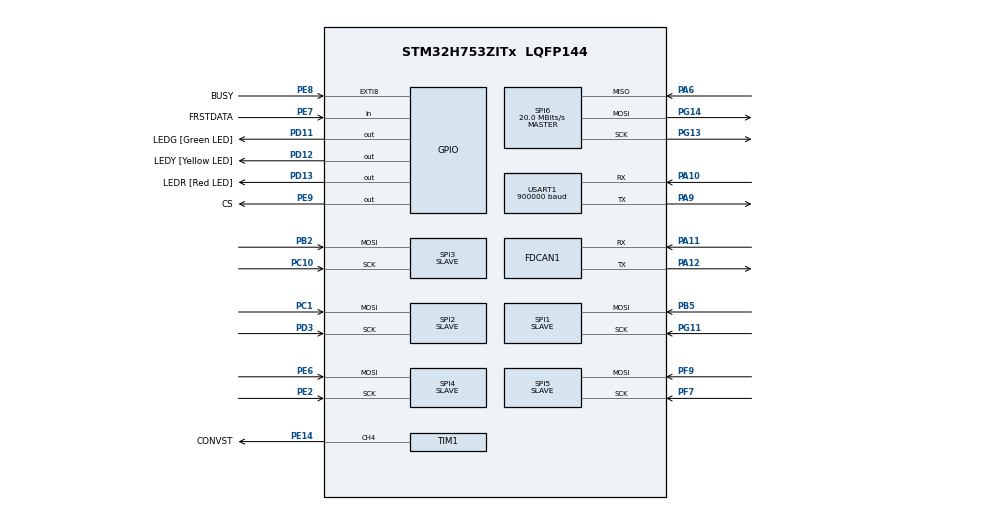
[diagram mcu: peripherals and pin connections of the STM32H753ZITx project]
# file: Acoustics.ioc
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ADC3.AWD1HighThreshold=16067
ADC3.AWD1ITMode=ENABLE
ADC3.AWD1LowThreshold=10900
ADC3.Channel-0\#ChannelRegularConversion=ADC_CHANNEL_TEMPSENSOR
ADC3.ClockPrescaler=ADC_CLOCK_ASYNC_DIV8
ADC3.ClockPrescalerADC3=ADC_CLOCK_ASYNC_DIV1
ADC3.ContinuousConvMode=DISABLE
ADC3.ConversionDataManagement=ADC_CONVERSIONDATA_DR
ADC3.EOCSelection=ADC_EOC_SINGLE_CONV
ADC3.EnableAnalogWatchDog1=true
ADC3.ExternalTrigConv=ADC_EXTERNALTRIG_T6_TRGO
ADC3.NbrOfConversion=1
ADC3.NbrOfConversionFlag=1
ADC3.OffsetNumber-0\#ChannelRegularConversion=ADC_OFFSET_NONE
ADC3.OffsetSignedSaturation-0\#ChannelRegularConversion=DISABLE
ADC3.Overrun=ADC_OVR_DATA_PRESERVED
ADC3.OversamplingMode=DISABLE
ADC3.Rank-0\#ChannelRegularConversion=1
ADC3.Ratio=1
ADC3.SamplingTime-0\#ChannelRegularConversion=ADC_SAMPLETIME_810CYCLES_5
ADC3.WatchdogChannel=ADC_CHANNEL_TEMPSENSOR
Bdma.ADC3.1.Direction=DMA_PERIPH_TO_MEMORY
Bdma.ADC3.1.EventEnable=DISABLE
Bdma.ADC3.1.Instance=BDMA_Channel1
Bdma.ADC3.1.MemDataAlignment=DMA_MDATAALIGN_HALFWORD
Bdma.ADC3.1.MemInc=DMA_MINC_DISABLE
Bdma.ADC3.1.Mode=DMA_CIRCULAR
Bdma.ADC3.1.PeriphDataAlignment=DMA_PDATAALIGN_HALFWORD
Bdma.ADC3.1.PeriphInc=DMA_PINC_DISABLE
Bdma.ADC3.1.Polarity=HAL_DMAMUX_REQ_GEN_RISING
Bdma.ADC3.1.Priority=DMA_PRIORITY_LOW
Bdma.ADC3.1.RequestNumber=1
Bdma.ADC3.1.SignalID=NONE
Bdma.ADC3.1.SyncEnable=DISABLE
Bdma.ADC3.1.SyncPolarity=HAL_DMAMUX_SYNC_NO_EVENT
Bdma.ADC3.1.SyncRequestNumber=1
Bdma.ADC3.1.SyncSignalID=NONE
Bdma.Request0=SPI6_RX
Bdma.Request1=ADC3
Bdma.RequestsNb=2
Bdma.SPI6_RX.0.Direction=DMA_PERIPH_TO_MEMORY
Bdma.SPI6_RX.0.EventEnable=DISABLE
Bdma.SPI6_RX.0.Instance=BDMA_Channel0
Bdma.SPI6_RX.0.MemDataAlignment=DMA_MDATAALIGN_HALFWORD
Bdma.SPI6_RX.0.MemInc=DMA_MINC_ENABLE
Bdma.SPI6_RX.0.Mode=DMA_CIRCULAR
Bdma.SPI6_RX.0.PeriphDataAlignment=DMA_PDATAALIGN_HALFWORD
Bdma.SPI6_RX.0.PeriphInc=DMA_PINC_DISABLE
Bdma.SPI6_RX.0.Polarity=HAL_DMAMUX_REQ_GEN_RISING
Bdma.SPI6_RX.0.Priority=DMA_PRIORITY_LOW
Bdma.SPI6_RX.0.RequestNumber=1
Bdma.SPI6_RX.0.SignalID=NONE
Bdma.SPI6_RX.0.SyncEnable=DISABLE
Bdma.SPI6_RX.0.SyncPolarity=HAL_DMAMUX_SYNC_NO_EVENT
Bdma.SPI6_RX.0.SyncRequestNumber=1
Bdma.SPI6_RX.0.SyncSignalID=NONE
CORTEX_M7.default_mode_Activation=1
Dma.Request0=SPI2_RX
Dma.Request1=SPI3_RX
Dma.Request2=SPI4_RX
Dma.Request3=SPI5_RX
Dma.Request4=SPI1_RX
Dma.Request5=TIM1_CH4
Dma.Request6=USART1_TX
Dma.SPI1_RX.4.Direction=DMA_PERIPH_TO_MEMORY
Dma.SPI1_RX.4.EventEnable=DISABLE
Dma.SPI1_RX.4.FIFOMode=DMA_FIFOMODE_DISABLE
Dma.SPI1_RX.4.Instance=DMA1_Stream0
Dma.SPI1_RX.4.MemDataAlignment=DMA_MDATAALIGN_HALFWORD
Dma.SPI1_RX.4.MemInc=DMA_MINC_ENABLE
Dma.SPI1_RX.4.Mode=DMA_CIRCULAR
Dma.SPI1_RX.4.PeriphDataAlignment=DMA_PDATAALIGN_HALFWORD
Dma.SPI1_RX.4.PeriphInc=DMA_PINC_DISABLE
Dma.SPI1_RX.4.Polarity=HAL_DMAMUX_REQ_GEN_RISING
Dma.SPI1_RX.4.Priority=DMA_PRIORITY_MEDIUM
Dma.SPI1_RX.4.RequestNumber=1
Dma.SPI1_RX.4.SignalID=NONE
Dma.SPI1_RX.4.SyncEnable=DISABLE
Dma.SPI1_RX.4.SyncPolarity=HAL_DMAMUX_SYNC_NO_EVENT
Dma.SPI1_RX.4.SyncRequestNumber=1
Dma.SPI1_RX.4.SyncSignalID=NONE
Dma.SPI2_RX.0.Direction=DMA_PERIPH_TO_MEMORY
Dma.SPI2_RX.0.EventEnable=DISABLE
Dma.SPI2_RX.0.FIFOMode=DMA_FIFOMODE_DISABLE
Dma.SPI2_RX.0.Instance=DMA1_Stream1
Dma.SPI2_RX.0.MemDataAlignment=DMA_MDATAALIGN_HALFWORD
Dma.SPI2_RX.0.MemInc=DMA_MINC_ENABLE
Dma.SPI2_RX.0.Mode=DMA_CIRCULAR
Dma.SPI2_RX.0.PeriphDataAlignment=DMA_PDATAALIGN_HALFWORD
Dma.SPI2_RX.0.PeriphInc=DMA_PINC_DISABLE
Dma.SPI2_RX.0.Polarity=HAL_DMAMUX_REQ_GEN_RISING
Dma.SPI2_RX.0.Priority=DMA_PRIORITY_VERY_HIGH
Dma.SPI2_RX.0.RequestNumber=1
Dma.SPI2_RX.0.SignalID=NONE
Dma.SPI2_RX.0.SyncEnable=DISABLE
Dma.SPI2_RX.0.SyncPolarity=HAL_DMAMUX_SYNC_NO_EVENT
Dma.SPI2_RX.0.SyncRequestNumber=1
Dma.SPI2_RX.0.SyncSignalID=NONE
Dma.SPI3_RX.1.Direction=DMA_PERIPH_TO_MEMORY
Dma.SPI3_RX.1.EventEnable=DISABLE
Dma.SPI3_RX.1.FIFOMode=DMA_FIFOMODE_DISABLE
Dma.SPI3_RX.1.Instance=DMA1_Stream2
Dma.SPI3_RX.1.MemDataAlignment=DMA_MDATAALIGN_HALFWORD
Dma.SPI3_RX.1.MemInc=DMA_MINC_ENABLE
Dma.SPI3_RX.1.Mode=DMA_CIRCULAR
Dma.SPI3_RX.1.PeriphDataAlignment=DMA_PDATAALIGN_HALFWORD
Dma.SPI3_RX.1.PeriphInc=DMA_PINC_DISABLE
Dma.SPI3_RX.1.Polarity=HAL_DMAMUX_REQ_GEN_RISING
Dma.SPI3_RX.1.Priority=DMA_PRIORITY_MEDIUM
Dma.SPI3_RX.1.RequestNumber=1
Dma.SPI3_RX.1.SignalID=NONE
Dma.SPI3_RX.1.SyncEnable=DISABLE
Dma.SPI3_RX.1.SyncPolarity=HAL_DMAMUX_SYNC_NO_EVENT
Dma.SPI3_RX.1.SyncRequestNumber=1
Dma.SPI3_RX.1.SyncSignalID=NONE
Dma.SPI4_RX.2.Direction=DMA_PERIPH_TO_MEMORY
Dma.SPI4_RX.2.EventEnable=DISABLE
Dma.SPI4_RX.2.FIFOMode=DMA_FIFOMODE_DISABLE
Dma.SPI4_RX.2.Instance=DMA1_Stream3
Dma.SPI4_RX.2.MemDataAlignment=DMA_MDATAALIGN_HALFWORD
Dma.SPI4_RX.2.MemInc=DMA_MINC_ENABLE
Dma.SPI4_RX.2.Mode=DMA_CIRCULAR
Dma.SPI4_RX.2.PeriphDataAlignment=DMA_PDATAALIGN_HALFWORD
Dma.SPI4_RX.2.PeriphInc=DMA_PINC_DISABLE
Dma.SPI4_RX.2.Polarity=HAL_DMAMUX_REQ_GEN_RISING
Dma.SPI4_RX.2.Priority=DMA_PRIORITY_MEDIUM
Dma.SPI4_RX.2.RequestNumber=1
Dma.SPI4_RX.2.SignalID=NONE
Dma.SPI4_RX.2.SyncEnable=DISABLE
Dma.SPI4_RX.2.SyncPolarity=HAL_DMAMUX_SYNC_NO_EVENT
Dma.SPI4_RX.2.SyncRequestNumber=1
Dma.SPI4_RX.2.SyncSignalID=NONE
Dma.SPI5_RX.3.Direction=DMA_PERIPH_TO_MEMORY
Dma.SPI5_RX.3.EventEnable=DISABLE
Dma.SPI5_RX.3.FIFOMode=DMA_FIFOMODE_DISABLE
Dma.SPI5_RX.3.Instance=DMA1_Stream4
Dma.SPI5_RX.3.MemDataAlignment=DMA_MDATAALIGN_HALFWORD
Dma.SPI5_RX.3.MemInc=DMA_MINC_ENABLE
Dma.SPI5_RX.3.Mode=DMA_CIRCULAR
Dma.SPI5_RX.3.PeriphDataAlignment=DMA_PDATAALIGN_HALFWORD
Dma.SPI5_RX.3.PeriphInc=DMA_PINC_DISABLE
Dma.SPI5_RX.3.Polarity=HAL_DMAMUX_REQ_GEN_RISING
Dma.SPI5_RX.3.Priority=DMA_PRIORITY_LOW
Dma.SPI5_RX.3.RequestNumber=1
Dma.SPI5_RX.3.SignalID=NONE
Dma.SPI5_RX.3.SyncEnable=DISABLE
Dma.SPI5_RX.3.SyncPolarity=HAL_DMAMUX_SYNC_NO_EVENT
Dma.SPI5_RX.3.SyncRequestNumber=1
Dma.SPI5_RX.3.SyncSignalID=NONE
Dma.TIM1_CH4.5.Direction=DMA_PERIPH_TO_MEMORY
Dma.TIM1_CH4.5.EventEnable=ENABLE
Dma.TIM1_CH4.5.FIFOMode=DMA_FIFOMODE_DISABLE
Dma.TIM1_CH4.5.Instance=DMA2_Stream0
Dma.TIM1_CH4.5.MemDataAlignment=DMA_MDATAALIGN_HALFWORD
Dma.TIM1_CH4.5.MemInc=DMA_MINC_ENABLE
Dma.TIM1_CH4.5.Mode=DMA_NORMAL
Dma.TIM1_CH4.5.PeriphDataAlignment=DMA_PDATAALIGN_HALFWORD
Dma.TIM1_CH4.5.PeriphInc=DMA_PINC_DISABLE
Dma.TIM1_CH4.5.Polarity=HAL_DMAMUX_REQ_GEN_RISING
Dma.TIM1_CH4.5.Priority=DMA_PRIORITY_LOW
Dma.TIM1_CH4.5.RequestNumber=1
Dma.TIM1_CH4.5.SignalID=NONE
Dma.TIM1_CH4.5.SyncEnable=DISABLE
Dma.TIM1_CH4.5.SyncPolarity=HAL_DMAMUX_SYNC_NO_EVENT
Dma.TIM1_CH4.5.SyncRequestNumber=1
Dma.TIM1_CH4.5.SyncSignalID=NONE
Dma.USART1_TX.6.Direction=DMA_MEMORY_TO_PERIPH
Dma.USART1_TX.6.EventEnable=DISABLE
Dma.USART1_TX.6.FIFOMode=DMA_FIFOMODE_DISABLE
Dma.USART1_TX.6.Instance=DMA1_Stream5
Dma.USART1_TX.6.MemDataAlignment=DMA_MDATAALIGN_BYTE
Dma.USART1_TX.6.MemInc=DMA_MINC_ENABLE
Dma.USART1_TX.6.Mode=DMA_NORMAL
Dma.USART1_TX.6.PeriphDataAlignment=DMA_PDATAALIGN_BYTE
Dma.USART1_TX.6.PeriphInc=DMA_PINC_DISABLE
Dma.USART1_TX.6.Polarity=HAL_DMAMUX_REQ_GEN_RISING
Dma.USART1_TX.6.Priority=DMA_PRIORITY_LOW
Dma.USART1_TX.6.RequestNumber=1
Dma.USART1_TX.6.SignalID=NONE
Dma.USART1_TX.6.SyncEnable=DISABLE
Dma.USART1_TX.6.SyncPolarity=HAL_DMAMUX_SYNC_NO_EVENT
Dma.USART1_TX.6.SyncRequestNumber=1
Dma.USART1_TX.6.SyncSignalID=NONE
FDCAN1.AutoRetransmission=DISABLE
FDCAN1.CalculateBaudRateNominal=500000
FDCAN1.CalculateTimeBitNominal=2000
FDCAN1.CalculateTimeQuantumNominal=12.5
FDCAN1.ClockCalibrationCCU=DISABLE
FDCAN1.DataSyncJumpWidth=10
FDCAN1.DataTimeSeg1=29
FDCAN1.DataTimeSeg2=10
FDCAN1.FrameFormat=FDCAN_FRAME_FD_BRS
FDCAN1.NominalPrescaler=1
FDCAN1.NominalSyncJumpWidth=40
FDCAN1.NominalTimeSeg1=119
FDCAN1.NominalTimeSeg2=40
FDCAN1.RxBufferSize=FDCAN_DATA_BYTES_16
FDCAN1.RxBuffersNbr=0
FDCAN1.RxFifo0ElmtSize=FDCAN_DATA_BYTES_16
FDCAN1.RxFifo0ElmtsNbr=8
FDCAN1.RxFifo1ElmtSize=FDCAN_DATA_BYTES_16
FDCAN1.RxFifo1ElmtsNbr=0
FDCAN1.StdFiltersNbr=1
FDCAN1.TxBuffersNbr=0
FDCAN1.TxElmtSize=FDCAN_DATA_BYTES_16
FDCAN1.TxFifoQueueElmtsNbr=16
Mcu.Family=STM32H7
Mcu.Name=STM32H753ZITx
Mcu.Package=LQFP144
Mdma.MDMA_Channel0.Request0=SW
Mdma.MDMA_Channel0.RequestsNb=1
Mdma.MDMA_Channel0.SW.0.BlockCount=1
Mdma.MDMA_Channel0.SW.0.BlockDataLength=256
Mdma.MDMA_Channel0.SW.0.BufferTransferLength=256
Mdma.MDMA_Channel0.SW.0.CircularMode=MDMA_LINEAR_LIST
Mdma.MDMA_Channel0.SW.0.DataAlignment=MDMA_DATAALIGN_PACKENABLE
Mdma.MDMA_Channel0.SW.0.DestBlockAddressOffset=0
Mdma.MDMA_Channel0.SW.0.DestBurst=MDMA_DEST_BURST_SINGLE
Mdma.MDMA_Channel0.SW.0.DestDataSize=MDMA_DEST_DATASIZE_WORD
Mdma.MDMA_Channel0.SW.0.DestinationInc=MDMA_DEST_INC_WORD
Mdma.MDMA_Channel0.SW.0.DstAddress=0
Mdma.MDMA_Channel0.SW.0.Endianness=MDMA_LITTLE_ENDIANNESS_PRESERVE
Mdma.MDMA_Channel0.SW.0.Instance=MDMA_Channel0
Mdma.MDMA_Channel0.SW.0.MaskAddress=0
Mdma.MDMA_Channel0.SW.0.MaskData=0
Mdma.MDMA_Channel0.SW.0.Priority=MDMA_PRIORITY_VERY_HIGH
Mdma.MDMA_Channel0.SW.0.Rank=First
Mdma.MDMA_Channel0.SW.0.SourceBlockAddressOffset=0
Mdma.MDMA_Channel0.SW.0.SourceBurst=MDMA_SOURCE_BURST_SINGLE
Mdma.MDMA_Channel0.SW.0.SourceDataSize=MDMA_SRC_DATASIZE_WORD
Mdma.MDMA_Channel0.SW.0.SourceInc=MDMA_SRC_INC_WORD
Mdma.MDMA_Channel0.SW.0.SrcAddress=0
Mdma.MDMA_Channel0.SW.0.TransferTriggerMode=MDMA_BLOCK_TRANSFER
Mdma.RequestSet0=MDMA_Channel0
Mdma.RequestSetsNb=1
NVIC.ADC3_IRQn=true\:0\:0\:false\:false\:true\:true\:true\:true
NVIC.BDMA_Channel0_IRQn=true\:0\:0\:false\:false\:true\:false\:true\:true
NVIC.BDMA_Channel1_IRQn=true\:0\:0\:false\:false\:true\:false\:true\:true
NVIC.DMA1_Stream0_IRQn=true\:14\:0\:true\:false\:true\:false\:true\:true
NVIC.DMA1_Stream1_IRQn=true\:14\:0\:true\:false\:true\:false\:true\:true
NVIC.DMA1_Stream2_IRQn=true\:14\:0\:true\:false\:true\:false\:true\:true
NVIC.DMA1_Stream3_IRQn=true\:14\:0\:true\:false\:true\:false\:true\:true
NVIC.DMA1_Stream4_IRQn=true\:14\:0\:true\:false\:true\:false\:true\:true
NVIC.DMA1_Stream5_IRQn=true\:0\:0\:false\:false\:true\:false\:true\:true
NVIC.DMA2_Stream0_IRQn=true\:0\:0\:false\:false\:true\:false\:true\:true
NVIC.DMAMUX1_OVR_IRQn=true\:0\:0\:false\:false\:true\:false\:true\:true
NVIC.EXTI9_5_IRQn=true\:2\:0\:true\:false\:true\:true\:true\:true
NVIC.FDCAN1_IT0_IRQn=true\:5\:0\:true\:false\:true\:true\:true\:true
NVIC.MDMA_IRQn=true\:0\:0\:false\:false\:true\:false\:true\:true
NVIC.PriorityGroup=NVIC_PRIORITYGROUP_4
NVIC.SPI1_IRQn=true\:13\:0\:true\:false\:true\:false\:true\:true
NVIC.SPI2_IRQn=true\:13\:0\:true\:false\:true\:false\:true\:true
NVIC.SPI3_IRQn=true\:13\:0\:true\:false\:true\:false\:true\:true
NVIC.SPI4_IRQn=true\:13\:0\:true\:false\:true\:false\:true\:true
NVIC.SPI5_IRQn=true\:13\:0\:true\:false\:true\:false\:true\:true
NVIC.SPI6_IRQn=true\:1\:0\:true\:false\:true\:true\:true\:true
PA10.GPIO_Speed=GPIO_SPEED_FREQ_VERY_HIGH
PA10.Mode=Asynchronous
PA10.Signal=USART1_RX
PA11.GPIO_Speed=GPIO_SPEED_FREQ_VERY_HIGH
PA11.Mode=FDCAN_Activate
PA11.Signal=FDCAN1_RX
PA12.GPIO_Speed=GPIO_SPEED_FREQ_VERY_HIGH
PA12.Mode=FDCAN_Activate
PA12.Signal=FDCAN1_TX
PA13\ (JTMS/SWDIO).Mode=Trace_Asynchronous_SW
PA13\ (JTMS/SWDIO).Signal=DEBUG_JTMS-SWDIO
PA14\ (JTCK/SWCLK).Mode=Trace_Asynchronous_SW
PA14\ (JTCK/SWCLK).Signal=DEBUG_JTCK-SWCLK
PA6.GPIO_Speed=GPIO_SPEED_FREQ_VERY_HIGH
PA6.Mode=Full_Duplex_Master
PA6.Signal=SPI6_MISO
PA9.GPIO_Speed=GPIO_SPEED_FREQ_VERY_HIGH
PA9.Mode=Asynchronous
PA9.Signal=USART1_TX
PB2.GPIO_Speed=GPIO_SPEED_FREQ_VERY_HIGH
PB2.Mode=RX_Only_Simplex_Unidirect_Slave
PB2.Signal=SPI3_MOSI
PB3\ (JTDO/TRACESWO).Mode=Trace_Asynchronous_SW
PB3\ (JTDO/TRACESWO).Signal=DEBUG_JTDO-SWO
PB5.GPIO_Mode=GPIO_MODE_AF_PP
PB5.GPIO_PuPd=GPIO_NOPULL
PB5.GPIO_Speed=GPIO_SPEED_FREQ_VERY_HIGH
PB5.Mode=RX_Only_Simplex_Unidirect_Slave
PB5.Signal=SPI1_MOSI
PC1.GPIO_Speed=GPIO_SPEED_FREQ_VERY_HIGH
PC1.Mode=RX_Only_Simplex_Unidirect_Slave
PC1.Signal=SPI2_MOSI
PC10.GPIO_Speed=GPIO_SPEED_FREQ_VERY_HIGH
PC10.Mode=RX_Only_Simplex_Unidirect_Slave
PC10.Signal=SPI3_SCK
PC14-OSC32_IN\ (OSC32_IN).Mode=LSE-External-Oscillator
PC14-OSC32_IN\ (OSC32_IN).Signal=RCC_OSC32_IN
PC15-OSC32_OUT\ (OSC32_OUT).Mode=LSE-External-Oscillator
PC15-OSC32_OUT\ (OSC32_OUT).Signal=RCC_OSC32_OUT
PD11.GPIO_Label=LEDG [Green LED]
PD11.Signal=GPIO_Output
PD12.GPIO_Label=LEDY [Yellow LED]
PD12.Signal=GPIO_Output
PD13.GPIO_Label=LEDR [Red LED]
PD13.Signal=GPIO_Output
PD3.GPIO_Speed=GPIO_SPEED_FREQ_VERY_HIGH
PD3.Mode=RX_Only_Simplex_Unidirect_Slave
PD3.Signal=SPI2_SCK
PE14.GPIO_Label=CONVST
PE14.GPIO_Speed=GPIO_SPEED_FREQ_VERY_HIGH
PE14.Signal=S_TIM1_CH4
PE2.GPIO_Speed=GPIO_SPEED_FREQ_VERY_HIGH
PE2.Mode=RX_Only_Simplex_Unidirect_Slave
PE2.Signal=SPI4_SCK
PE6.GPIO_Speed=GPIO_SPEED_FREQ_VERY_HIGH
PE6.Mode=RX_Only_Simplex_Unidirect_Slave
PE6.Signal=SPI4_MOSI
PE7.GPIO_Label=FRSTDATA
PE7.Signal=GPIO_Input
PE8.GPIO_Label=BUSY
PE8.Signal=GPXTI8
PE9.GPIO_Label=CS
PE9.PinState=GPIO_PIN_SET
PE9.Signal=GPIO_Output
PF7.GPIO_Speed=GPIO_SPEED_FREQ_VERY_HIGH
PF7.Mode=RX_Only_Simplex_Unidirect_Slave
PF7.Signal=SPI5_SCK
PF9.GPIO_Speed=GPIO_SPEED_FREQ_VERY_HIGH
PF9.Mode=RX_Only_Simplex_Unidirect_Slave
PF9.Signal=SPI5_MOSI
PG11.GPIO_Mode=GPIO_MODE_AF_PP
PG11.GPIO_PuPd=GPIO_NOPULL
PG11.GPIO_Speed=GPIO_SPEED_FREQ_VERY_HIGH
PG11.Mode=RX_Only_Simplex_Unidirect_Slave
PG11.Signal=SPI1_SCK
PG13.GPIO_Speed=GPIO_SPEED_FREQ_VERY_HIGH
PG13.Mode=Full_Duplex_Master
PG13.Signal=SPI6_SCK
PG14.GPIO_Speed=GPIO_SPEED_FREQ_VERY_HIGH
PG14.Mode=Full_Duplex_Master
PG14.Signal=SPI6_MOSI
PH0-OSC_IN\ (PH0).Mode=HSE-External-Clock-Source
PH0-OSC_IN\ (PH0).Signal=RCC_OSC_IN
ProjectManager.HeapSize=0x200
ProjectManager.StackSize=0x400
ProjectManager.TargetToolchain=STM32CubeIDE
RCC.ADCFreq_Value=80000000
RCC.APB1Freq_Value=120000000
RCC.APB2Freq_Value=120000000
RCC.APB3Freq_Value=120000000
RCC.APB4Freq_Value=120000000
RCC.CKPERSourceSelection=RCC_CLKPSOURCE_HSE
RCC.CortexFreq_Value=480000000
RCC.D1PPRE=RCC_APB3_DIV2
RCC.D2PPRE1=RCC_APB1_DIV2
RCC.D2PPRE2=RCC_APB2_DIV2
RCC.D3PPRE=RCC_APB4_DIV2
RCC.DIVM1=4
RCC.DIVM2=16
RCC.DIVN1=96
RCC.DIVN2=128
RCC.DIVN3=128
RCC.DIVP2=4
RCC.DIVQ1=5
RCC.DIVQ2=4
RCC.FDCANCLockSelection=RCC_FDCANCLKSOURCE_PLL2
RCC.FLatency-AdvancedSettings=FLASH_LATENCY_0
RCC.HCLKFreq_Value=240000000
RCC.HPRE=RCC_HCLK_DIV2
RCC.HSE_VALUE=40000000
RCC.PLL1_VCI_Range-AdvancedSettings=RCC_PLL1VCIRANGE_0
RCC.PLL1_VCO_SEL-AdvancedSettings=RCC_PLL1VCOMEDIUM
RCC.PLL2FRACN=0
RCC.PLL2_VCI_Range-AdvancedSettings=RCC_PLL2VCIRANGE_0
RCC.PLL2_VCO_SEL-AdvancedSettings=RCC_PLL2VCOMEDIUM
RCC.PLL3FRACN=0
RCC.PLL3_VCI_Range-AdvancedSettings=RCC_PLL3VCIRANGE_0
RCC.PLL3_VCO_SEL-AdvancedSettings=RCC_PLL3VCOWIDE
RCC.PLLFRACN=0
RCC.PLLSourceVirtual=RCC_PLLSOURCE_HSE
RCC.RTCClockSelection=RCC_RTCCLKSOURCE_LSE
RCC.SPI123CLockSelection=RCC_SPI123CLKSOURCE_PLL2
RCC.SPI6CLockSelection=RCC_SPI6CLKSOURCE_PLL2
RCC.SYSCLKFreq_VALUE=480000000
RCC.SYSCLKSource=RCC_SYSCLKSOURCE_PLLCLK
RCC.Spi45ClockSelection=RCC_SPI45CLKSOURCE_PLL2
RCC.USBFreq_Value=192000000
SH.S_TIM1_CH4.0=TIM1_CH4,PWM Generation4 CH4
SPI1.CLKPhase=SPI_PHASE_2EDGE
SPI1.CLKPolarity=SPI_POLARITY_HIGH
SPI1.DataSize=SPI_DATASIZE_16BIT
SPI1.Direction=SPI_DIRECTION_2LINES_RXONLY
SPI1.MasterKeepIOState=SPI_MASTER_KEEP_IO_STATE_DISABLE
SPI1.Mode=SPI_MODE_SLAVE
SPI1.VirtualType=VM_SLAVE
SPI2.CLKPhase=SPI_PHASE_2EDGE
SPI2.CLKPolarity=SPI_POLARITY_HIGH
SPI2.DataSize=SPI_DATASIZE_16BIT
SPI2.Direction=SPI_DIRECTION_2LINES_RXONLY
SPI2.Mode=SPI_MODE_SLAVE
SPI2.VirtualType=VM_SLAVE
SPI3.CLKPhase=SPI_PHASE_2EDGE
SPI3.CLKPolarity=SPI_POLARITY_HIGH
SPI3.DataSize=SPI_DATASIZE_16BIT
SPI3.Direction=SPI_DIRECTION_2LINES_RXONLY
SPI3.Mode=SPI_MODE_SLAVE
SPI3.VirtualType=VM_SLAVE
SPI4.CLKPhase=SPI_PHASE_2EDGE
SPI4.CLKPolarity=SPI_POLARITY_HIGH
SPI4.DataSize=SPI_DATASIZE_16BIT
SPI4.Direction=SPI_DIRECTION_2LINES_RXONLY
SPI4.Mode=SPI_MODE_SLAVE
SPI4.VirtualType=VM_SLAVE
SPI5.CLKPhase=SPI_PHASE_2EDGE
SPI5.CLKPolarity=SPI_POLARITY_HIGH
SPI5.DataSize=SPI_DATASIZE_16BIT
SPI5.Direction=SPI_DIRECTION_2LINES_RXONLY
SPI5.Mode=SPI_MODE_SLAVE
SPI5.VirtualType=VM_SLAVE
SPI6.BaudRatePrescaler=SPI_BAUDRATEPRESCALER_4
SPI6.CLKPhase=SPI_PHASE_1EDGE
SPI6.CLKPolarity=SPI_POLARITY_HIGH
SPI6.CalculateBaudRate=20.0 MBits/s
SPI6.DataSize=SPI_DATASIZE_16BIT
SPI6.Direction=SPI_DIRECTION_2LINES
SPI6.MasterKeepIOState=SPI_MASTER_KEEP_IO_STATE_ENABLE
SPI6.Mode=SPI_MODE_MASTER
SPI6.VirtualType=VM_MASTER
TIM1.Channel-PWM\ Generation4\ CH4=TIM_CHANNEL_4
TIM1.OC4Preload_PWM=ENABLE
TIM1.Period=1919
TIM1.Prescaler=0
TIM1.Pulse-PWM\ Generation4\ CH4=10
TIM6.Period=249
TIM6.Prescaler=3749
TIM6.TIM_MasterOutputTrigger=TIM_TRGO_UPDATE
USART1.BaudRate=900000
USART1.OverSampling=UART_OVERSAMPLING_16
USART1.VirtualMode-Asynchronous=VM_ASYNC
VP_ADC3_TempSens_Input.Mode=IN-TempSens
VP_CRC_VS_CRC.Mode=CRC_Activate
VP_MEMORYMAP_VS_MEMORYMAP.Mode=CurAppReg
VP_RTC_VS_RTC_Activate.Mode=RTC_Enabled
VP_TIM1_VS_ClockSourceINT.Mode=Internal
VP_TIM6_VS_ClockSourceINT.Mode=Enable_Timer
board=custom

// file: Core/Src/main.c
/* USER CODE BEGIN Header */
/**
 ******************************************************************************
 * @file           : main.c
 * @brief          : Main program body
 ******************************************************************************
 * @attention
 *
 * Copyright (c) 2026 STMicroelectronics.
 * All rights reserved.
 *
 * This software is licensed under terms that can be found in the LICENSE file
 * in the root directory of this software component.
 * If no LICENSE file comes with this software, it is provided AS-IS.
 *
 ******************************************************************************
 */
/* USER CODE END Header */
#include "main.h"

/* USER CODE BEGIN Includes */
#include "ad7606_driver.h"

#include "acoustics.h"
#include "can_interface.h"
#include "debug.h"
#include "interrupts.h"
#include <hydrophone_interface.h>

#include "utils.h"
#include "memory_placement.h"
#include "embedded_macros.h"

#include "find_peaks.h"
#include "dsp.h"
#include "cwt.h"
#include "hilbert.h"

#include "fast_mdma.h"
#include "stm_temp_driver.h"
#include "tdoa.h"

#include "stm32h753xx.h"
#include "stm32h7xx_hal.h"
#include "stm32h7xx_hal_gpio.h"
#include "stm32h7xx_hal_gpio_ex.h"
#include "stm32h7xx_hal_spi.h"
#include "stm32h7xx_hal_mdma.h"
#include "stm32h7xx_hal_fdcan.h"

#include "arm_math_types.h"
#include "arm_math.h"
#include "arm_const_structs.h"

#include <stdio.h>
#include <stdbool.h>
#include <stdint.h>
#include <stdlib.h>

/* USER CODE END Includes */

ADC_HandleTypeDef hadc3;
DMA_HandleTypeDef hdma_adc3;

CRC_HandleTypeDef hcrc;

FDCAN_HandleTypeDef hfdcan1;

RTC_HandleTypeDef hrtc;

SPI_HandleTypeDef hspi1;
SPI_HandleTypeDef hspi2;
SPI_HandleTypeDef hspi3;
SPI_HandleTypeDef hspi4;
SPI_HandleTypeDef hspi5;
SPI_HandleTypeDef hspi6;
DMA_HandleTypeDef hdma_spi1_rx;
DMA_HandleTypeDef hdma_spi2_rx;
DMA_HandleTypeDef hdma_spi3_rx;
DMA_HandleTypeDef hdma_spi4_rx;
DMA_HandleTypeDef hdma_spi5_rx;
DMA_HandleTypeDef hdma_spi6_rx;

TIM_HandleTypeDef htim1;
TIM_HandleTypeDef htim6;
DMA_HandleTypeDef hdma_tim1_ch4;

UART_HandleTypeDef huart1;
DMA_HandleTypeDef hdma_usart1_tx;

MDMA_HandleTypeDef hmdma_mdma_channel0_sw_0;
/* USER CODE BEGIN PV */

PLACE_IN_DTCM volatile statemachine_state program_state;
PLACE_IN_DTCM volatile statemachine_state prev_program_state;
PLACE_IN_DTCM uint8_t stale_data_patience;
PLACE_IN_DTCM uint8_t previous_target_block;

PLACE_IN_D3_SRAM float32_t stm32_temp;

/* USER CODE END PV */

void SystemClock_Config(void);
void PeriphCommonClock_Config(void);
static void MPU_Config(void);
static void MX_GPIO_Init(void);
static void MX_DMA_Init(void);
static void MX_MDMA_Init(void);
static void MX_BDMA_Init(void);
static void MX_FDCAN1_Init(void);
static void MX_SPI1_Init(void);
static void MX_SPI2_Init(void);
static void MX_SPI3_Init(void);
static void MX_SPI4_Init(void);
static void MX_SPI5_Init(void);
static void MX_SPI6_Init(void);
static void MX_USART1_UART_Init(void);
static void MX_CRC_Init(void);
static void MX_TIM1_Init(void);
static void MX_RTC_Init(void);
static void MX_ADC3_Init(void);
static void MX_TIM6_Init(void);

/* USER CODE BEGIN 0 */

void SWO_Init(void)
{
    /* Enable ITM and DWT */
    CoreDebug->DEMCR |= CoreDebug_DEMCR_TRCENA_Msk;

    /* ITM unlock */
    ITM->LAR = 0xC5ACCE55;

    /* Enable ITM port 0 */
    ITM->TCR |= ITM_TCR_ITMENA_Msk;
    ITM->TER |= (1UL << 0);  // Enable stimulus port 0
}

bool stale_data(uint8_t target_block){
	if(target_block == previous_target_block){

		if(unlikely(stale_data_patience-- == 0)){
			return true;
		}
	}else{
		stale_data_patience = STALE_DATA_PATIENCE;
	}
	previous_target_block = target_block;
	return false;
}
/* USER CODE END 0 */

int main(void)
{

  /* USER CODE BEGIN 1 */
	/*
	 * If hydrophone stream stops unexpectedly then:
	 * MAKE SURE HAL_SPI_IRQHandler IS NOT CALLED!!!!
	 * It WILL be there after every code generation
	 */
  /* USER CODE END 1 */

  /* MPU Configuration--------------------------------------------------------*/
  MPU_Config();

  /* MCU Configuration--------------------------------------------------------*/

  /* Reset of all peripherals, Initializes the Flash interface and the Systick. */
  HAL_Init();

  /* USER CODE BEGIN Init */
  SWO_Init();

  /* USER CODE END Init */

  /* Configure the system clock */
  SystemClock_Config();

  /* Configure the peripherals common clocks */
  PeriphCommonClock_Config();

  /* USER CODE BEGIN SysInit */
  utils_DWT_init();

  /* USER CODE END SysInit */

  /* Initialize all configured peripherals */
  MX_GPIO_Init();
  MX_DMA_Init();
  MX_MDMA_Init();
  MX_BDMA_Init();
  MX_FDCAN1_Init();
  MX_SPI1_Init();
  MX_SPI2_Init();
  MX_SPI3_Init();
  MX_SPI4_Init();
  MX_SPI5_Init();
  MX_SPI6_Init();
  MX_USART1_UART_Init();
  MX_CRC_Init();
  MX_TIM1_Init();
  MX_RTC_Init();
  MX_ADC3_Init();
  MX_TIM6_Init();
  /* USER CODE BEGIN 2 */
  //MDMA_UserInit();
	HAL_GPIO_WritePin(GREEN_LED, GPIO_PIN_SET);
	uint8_t msg[] = "USART1 OK\r\n";
	HAL_UART_Transmit(&huart1, msg, sizeof(msg) - 1, 100);
	can_init();
	stm_temp_sensor_init(&hadc3, &htim6);

//	float32_t hydrophone_positions_temp[N_HYDROPHONES][3] = { //this is in cm and must be converted
//			{0.0,0.0,0.0},
//			{0.0,0.0,0.0},
//			{32.3,-4.3,3.66},
//			{-6.6,34.7,1.66},
//			{-4.6,0.0,-34.34}
//	}; // these are the positions on the acoustics stand

	/*
	 * These are the hydrophone positions measured in meters
	 * Axis:
	 * 	positive x direction is forwards on the drone
	 * 	positive y direction is to the right on the drone
	 * 	positive z direction is downwards on the drone
	 *
	 * Each index corresponds to a filter:
	 * 	index 0 -> filter 1
	 * 	index 1 -> filter 2
	 * 	...
	 *
	 * The direction measured by acoustics is the direction from the origin of the hydrophones coordinate system
	 */
	float32_t hydrophone_positions_actual[N_HYDROPHONES][3] = {
			{ 0.130, 0.235,-0.215},
			{-0.130,-0.235, 0.215},
			{-0.130, 0.235,-0.215},
			{ 0.130,-0.235,-0.215},
			{ 0.130, 0.235, 0.215},
	};

	stale_data_patience = STALE_DATA_PATIENCE;
	previous_target_block = 0xFF;

	acoustics_init();
	hydrophone_interface_init(hydrophone_positions_actual);

	hydrophone_interface_start_datastream();
	program_state = STATE_SEARCHING;

  /* USER CODE END 2 */

  /* Infinite loop */
  /* USER CODE BEGIN WHILE */
	HAL_GPIO_WritePin(YELLOW_LED, GPIO_PIN_SET);

	uint8_t target_block = 0;
	uint8_t detection_patience = DETECTION_PATIENCE;

    while (1) {
    	switch(program_state){
    	case(STATE_SEARCHING): //STATE_SEARCHING
    		while(program_state == STATE_SEARCHING){
    			target_block = hydrophone_buffers_get_detection_block_pos_fast();
				uint8_t processing_half = !mdma_half;
				fast_MDMA_copy_block(hydrophone_buffers[0][target_block], detection_buffer[mdma_half], &hmdma_mdma_channel0_sw_0);

				hydrophone_interface_update_temp();

				if(unlikely(stale_data(target_block))){
					Error_Handler();
				}

				if(unlikely(acoustics_signal_present(processing_half))){
					program_state = STATE_PROCESSING;
					detection_patience = DETECTION_PATIENCE;
				}

				hydrophone_interface_wait_for_mdma();
    		}
		break;
    	case(STATE_PROCESSING):
			hydrophone_interface_stop_datastream();
			HAL_GPIO_WritePin(GREEN_LED, GPIO_PIN_RESET);

			can_ping();

			acoustics_prepare_data(target_block);
			acoustics_process_data();
			acoustics_clean_data();

			if(program_state == STATE_CAN_COMMUNICATE){
				prev_program_state = STATE_SIGNAL_PRESENT;
			}else{
				program_state = STATE_SIGNAL_PRESENT;
			}
			hydrophone_interface_restart_spi_and_buffers();
			hydrophone_interface_start_datastream();
			HAL_GPIO_WritePin(GREEN_LED, GPIO_PIN_SET);
		break;

    	case(STATE_SIGNAL_PRESENT): //For when the signal is still going even after we finished processing its arrival
    		while((program_state == STATE_SIGNAL_PRESENT) && detection_patience){
    			target_block = hydrophone_buffers_get_detection_block_pos_fast();
    			uint8_t processing_half = !mdma_half;
    			fast_MDMA_copy_block(hydrophone_buffers[0][target_block], detection_buffer[mdma_half], &hmdma_mdma_channel0_sw_0);

    			hydrophone_interface_update_temp();

				if(unlikely(stale_data(target_block))){
					HAL_GPIO_WritePin(RED_LED, GPIO_PIN_SET);
					utils_DWT_delay_ms(1000);
					Error_Handler();
				}

    			detection_patience--;
    			if(unlikely(acoustics_signal_present(processing_half))){
    				detection_patience = DETECTION_PATIENCE;
    			}

    			if(detection_patience == 0){
    				if(program_state == STATE_CAN_COMMUNICATE){
    					prev_program_state = STATE_SEARCHING;
    				}else{
    					program_state = STATE_SEARCHING;
    				}
    			}

    			hydrophone_interface_wait_for_mdma();
    		}
		break;
    	case(STATE_CAN_COMMUNICATE): //For when a can request is on the line
			can_handle_requests();
    		if(prev_program_state != STATE_CAN_COMMUNICATE){
    			program_state = prev_program_state;
    		}else{
    			program_state = STATE_ERROR;
    		}

		break;
    	case(STATE_STOPPED): // For when we received a stop request
    		can_stopped();
    		utils_DWT_delay_ms(500);
		break;
    	case(STATE_ERROR):
    			Error_Handler();
    	break;
    	default:
    		program_state = STATE_ERROR;
    	break;
    	}
    /* USER CODE END WHILE */

    /* USER CODE BEGIN 3 */
    }
    Error_Handler();
  /* USER CODE END 3 */
}

void SystemClock_Config(void)
{
  RCC_OscInitTypeDef RCC_OscInitStruct = {0};
  RCC_ClkInitTypeDef RCC_ClkInitStruct = {0};

  /** Supply configuration update enable
  */
  HAL_PWREx_ConfigSupply(PWR_LDO_SUPPLY);

  /** Configure the main internal regulator output voltage
  */
  __HAL_PWR_VOLTAGESCALING_CONFIG(PWR_REGULATOR_VOLTAGE_SCALE0);

  while(!__HAL_PWR_GET_FLAG(PWR_FLAG_VOSRDY)) {}

  /** Configure LSE Drive Capability
  */
  HAL_PWR_EnableBkUpAccess();
  __HAL_RCC_LSEDRIVE_CONFIG(RCC_LSEDRIVE_LOW);

  /** Initializes the RCC Oscillators according to the specified parameters
  * in the RCC_OscInitTypeDef structure.
  */
  RCC_OscInitStruct.OscillatorType = RCC_OSCILLATORTYPE_HSE|RCC_OSCILLATORTYPE_LSE;
  RCC_OscInitStruct.HSEState = RCC_HSE_BYPASS;
  RCC_OscInitStruct.LSEState = RCC_LSE_ON;
  RCC_OscInitStruct.PLL.PLLState = RCC_PLL_ON;
  RCC_OscInitStruct.PLL.PLLSource = RCC_PLLSOURCE_HSE;
  RCC_OscInitStruct.PLL.PLLM = 4;
  RCC_OscInitStruct.PLL.PLLN = 96;
  RCC_OscInitStruct.PLL.PLLP = 2;
  RCC_OscInitStruct.PLL.PLLQ = 5;
  RCC_OscInitStruct.PLL.PLLR = 2;
  RCC_OscInitStruct.PLL.PLLRGE = RCC_PLL1VCIRANGE_3;
  RCC_OscInitStruct.PLL.PLLVCOSEL = RCC_PLL1VCOWIDE;
  RCC_OscInitStruct.PLL.PLLFRACN = 0;
  if (HAL_RCC_OscConfig(&RCC_OscInitStruct) != HAL_OK)
  {
    Error_Handler();
  }

  /** Initializes the CPU, AHB and APB buses clocks
  */
  RCC_ClkInitStruct.ClockType = RCC_CLOCKTYPE_HCLK|RCC_CLOCKTYPE_SYSCLK
                              |RCC_CLOCKTYPE_PCLK1|RCC_CLOCKTYPE_PCLK2
                              |RCC_CLOCKTYPE_D3PCLK1|RCC_CLOCKTYPE_D1PCLK1;
  RCC_ClkInitStruct.SYSCLKSource = RCC_SYSCLKSOURCE_PLLCLK;
  RCC_ClkInitStruct.SYSCLKDivider = RCC_SYSCLK_DIV1;
  RCC_ClkInitStruct.AHBCLKDivider = RCC_HCLK_DIV2;
  RCC_ClkInitStruct.APB3CLKDivider = RCC_APB3_DIV2;
  RCC_ClkInitStruct.APB1CLKDivider = RCC_APB1_DIV2;
  RCC_ClkInitStruct.APB2CLKDivider = RCC_APB2_DIV2;
  RCC_ClkInitStruct.APB4CLKDivider = RCC_APB4_DIV2;

  if (HAL_RCC_ClockConfig(&RCC_ClkInitStruct, FLASH_LATENCY_4) != HAL_OK)
  {
    Error_Handler();
  }
}

void PeriphCommonClock_Config(void)
{
  RCC_PeriphCLKInitTypeDef PeriphClkInitStruct = {0};

  /** Initializes the peripherals clock
  */
  PeriphClkInitStruct.PeriphClockSelection = RCC_PERIPHCLK_SPI6|RCC_PERIPHCLK_ADC
                              |RCC_PERIPHCLK_SPI3|RCC_PERIPHCLK_SPI2
                              |RCC_PERIPHCLK_SPI1|RCC_PERIPHCLK_SPI4
                              |RCC_PERIPHCLK_SPI5|RCC_PERIPHCLK_FDCAN;
  PeriphClkInitStruct.PLL2.PLL2M = 16;
  PeriphClkInitStruct.PLL2.PLL2N = 128;
  PeriphClkInitStruct.PLL2.PLL2P = 4;
  PeriphClkInitStruct.PLL2.PLL2Q = 4;
  PeriphClkInitStruct.PLL2.PLL2R = 2;
  PeriphClkInitStruct.PLL2.PLL2RGE = RCC_PLL2VCIRANGE_1;
  PeriphClkInitStruct.PLL2.PLL2VCOSEL = RCC_PLL2VCOMEDIUM;
  PeriphClkInitStruct.PLL2.PLL2FRACN = 0;
  PeriphClkInitStruct.Spi123ClockSelection = RCC_SPI123CLKSOURCE_PLL2;
  PeriphClkInitStruct.Spi45ClockSelection = RCC_SPI45CLKSOURCE_PLL2;
  PeriphClkInitStruct.FdcanClockSelection = RCC_FDCANCLKSOURCE_PLL2;
  PeriphClkInitStruct.AdcClockSelection = RCC_ADCCLKSOURCE_PLL2;
  PeriphClkInitStruct.Spi6ClockSelection = RCC_SPI6CLKSOURCE_PLL2;
  if (HAL_RCCEx_PeriphCLKConfig(&PeriphClkInitStruct) != HAL_OK)
  {
    Error_Handler();
  }
}

static void MX_ADC3_Init(void)
{

  ADC_AnalogWDGConfTypeDef AnalogWDGConfig = {0};
  ADC_ChannelConfTypeDef sConfig = {0};

  /** Common config
  */
  hadc3.Instance = ADC3;
  hadc3.Init.ClockPrescaler = ADC_CLOCK_ASYNC_DIV8;
  hadc3.Init.Resolution = ADC_RESOLUTION_16B;
  hadc3.Init.ScanConvMode = ADC_SCAN_DISABLE;
  hadc3.Init.EOCSelection = ADC_EOC_SINGLE_CONV;
  hadc3.Init.LowPowerAutoWait = DISABLE;
  hadc3.Init.ContinuousConvMode = DISABLE;
  hadc3.Init.NbrOfConversion = 1;
  hadc3.Init.DiscontinuousConvMode = DISABLE;
  hadc3.Init.ExternalTrigConv = ADC_EXTERNALTRIG_T6_TRGO;
  hadc3.Init.ExternalTrigConvEdge = ADC_EXTERNALTRIGCONVEDGE_RISING;
  hadc3.Init.ConversionDataManagement = ADC_CONVERSIONDATA_DR;
  hadc3.Init.Overrun = ADC_OVR_DATA_PRESERVED;
  hadc3.Init.LeftBitShift = ADC_LEFTBITSHIFT_NONE;
  hadc3.Init.OversamplingMode = DISABLE;
  hadc3.Init.Oversampling.Ratio = 1;
  if (HAL_ADC_Init(&hadc3) != HAL_OK)
  {
    Error_Handler();
  }

  /** Configure Analog WatchDog 1
  */
  AnalogWDGConfig.WatchdogNumber = ADC_ANALOGWATCHDOG_1;
  AnalogWDGConfig.WatchdogMode = ADC_ANALOGWATCHDOG_SINGLE_REG;
  AnalogWDGConfig.Channel = ADC_CHANNEL_TEMPSENSOR;
  AnalogWDGConfig.ITMode = ENABLE;
  AnalogWDGConfig.HighThreshold = 16067;
  AnalogWDGConfig.LowThreshold = 10900;
  if (HAL_ADC_AnalogWDGConfig(&hadc3, &AnalogWDGConfig) != HAL_OK)
  {
    Error_Handler();
  }

  /** Configure Regular Channel
  */
  sConfig.Channel = ADC_CHANNEL_TEMPSENSOR;
  sConfig.Rank = ADC_REGULAR_RANK_1;
  sConfig.SamplingTime = ADC_SAMPLETIME_810CYCLES_5;
  sConfig.SingleDiff = ADC_SINGLE_ENDED;
  sConfig.OffsetNumber = ADC_OFFSET_NONE;
  sConfig.Offset = 0;
  sConfig.OffsetSignedSaturation = DISABLE;
  if (HAL_ADC_ConfigChannel(&hadc3, &sConfig) != HAL_OK)
  {
    Error_Handler();
  }

}

static void MX_CRC_Init(void)
{

  hcrc.Instance = CRC;
  hcrc.Init.DefaultPolynomialUse = DEFAULT_POLYNOMIAL_ENABLE;
  hcrc.Init.DefaultInitValueUse = DEFAULT_INIT_VALUE_ENABLE;
  hcrc.Init.InputDataInversionMode = CRC_INPUTDATA_INVERSION_NONE;
  hcrc.Init.OutputDataInversionMode = CRC_OUTPUTDATA_INVERSION_DISABLE;
  hcrc.InputDataFormat = CRC_INPUTDATA_FORMAT_BYTES;
  if (HAL_CRC_Init(&hcrc) != HAL_OK)
  {
    Error_Handler();
  }

}

static void MX_FDCAN1_Init(void)
{

  hfdcan1.Instance = FDCAN1;
  hfdcan1.Init.FrameFormat = FDCAN_FRAME_FD_BRS;
  hfdcan1.Init.Mode = FDCAN_MODE_NORMAL;
  hfdcan1.Init.AutoRetransmission = DISABLE;
  hfdcan1.Init.TransmitPause = DISABLE;
  hfdcan1.Init.ProtocolException = DISABLE;
  hfdcan1.Init.NominalPrescaler = 1;
  hfdcan1.Init.NominalSyncJumpWidth = 40;
  hfdcan1.Init.NominalTimeSeg1 = 119;
  hfdcan1.Init.NominalTimeSeg2 = 40;
  hfdcan1.Init.DataPrescaler = 1;
  hfdcan1.Init.DataSyncJumpWidth = 10;
  hfdcan1.Init.DataTimeSeg1 = 29;
  hfdcan1.Init.DataTimeSeg2 = 10;
  hfdcan1.Init.MessageRAMOffset = 0;
  hfdcan1.Init.StdFiltersNbr = 1;
  hfdcan1.Init.ExtFiltersNbr = 0;
  hfdcan1.Init.RxFifo0ElmtsNbr = 8;
  hfdcan1.Init.RxFifo0ElmtSize = FDCAN_DATA_BYTES_16;
  hfdcan1.Init.RxFifo1ElmtsNbr = 0;
  hfdcan1.Init.RxFifo1ElmtSize = FDCAN_DATA_BYTES_16;
  hfdcan1.Init.RxBuffersNbr = 0;
  hfdcan1.Init.RxBufferSize = FDCAN_DATA_BYTES_16;
  hfdcan1.Init.TxEventsNbr = 0;
  hfdcan1.Init.TxBuffersNbr = 0;
  hfdcan1.Init.TxFifoQueueElmtsNbr = 16;
  hfdcan1.Init.TxFifoQueueMode = FDCAN_TX_FIFO_OPERATION;
  hfdcan1.Init.TxElmtSize = FDCAN_DATA_BYTES_16;
  if (HAL_FDCAN_Init(&hfdcan1) != HAL_OK)
  {
    Error_Handler();
  }
  /* USER CODE BEGIN FDCAN1_Init 2 */
  FDCAN_FilterTypeDef filterConfig;
  filterConfig.IdType       = FDCAN_STANDARD_ID;
  filterConfig.FilterIndex  = 0;
  filterConfig.FilterType   = FDCAN_FILTER_MASK;
  filterConfig.FilterConfig = FDCAN_FILTER_TO_RXFIFO0;
  filterConfig.FilterID1    = 0x000;   // ID
  filterConfig.FilterID2    = 0x000;   // Mask: 0x000 = accept all

  HAL_FDCAN_ConfigFilter(&hfdcan1, &filterConfig);

  // Reject non-matching and remote frames (recommended)
  HAL_FDCAN_ConfigGlobalFilter(
      &hfdcan1,
      FDCAN_REJECT,         // Non-matching standard
      FDCAN_REJECT,         // Non-matching extended
      FDCAN_FILTER_REMOTE,  // Remote standard
      FDCAN_FILTER_REMOTE   // Remote extended
  );
  /* USER CODE END FDCAN1_Init 2 */

}

static void MX_RTC_Init(void)
{

  /** Initialize RTC Only
  */
  hrtc.Instance = RTC;
  hrtc.Init.HourFormat = RTC_HOURFORMAT_24;
  hrtc.Init.AsynchPrediv = 127;
  hrtc.Init.SynchPrediv = 255;
  hrtc.Init.OutPut = RTC_OUTPUT_DISABLE;
  hrtc.Init.OutPutPolarity = RTC_OUTPUT_POLARITY_HIGH;
  hrtc.Init.OutPutType = RTC_OUTPUT_TYPE_OPENDRAIN;
  hrtc.Init.OutPutRemap = RTC_OUTPUT_REMAP_NONE;
  if (HAL_RTC_Init(&hrtc) != HAL_OK)
  {
    Error_Handler();
  }

}

static void MX_SPI1_Init(void)
{

  /* SPI1 parameter configuration*/
  hspi1.Instance = SPI1;
  hspi1.Init.Mode = SPI_MODE_SLAVE;
  hspi1.Init.Direction = SPI_DIRECTION_2LINES_RXONLY;
  hspi1.Init.DataSize = SPI_DATASIZE_16BIT;
  hspi1.Init.CLKPolarity = SPI_POLARITY_HIGH;
  hspi1.Init.CLKPhase = SPI_PHASE_2EDGE;
  hspi1.Init.NSS = SPI_NSS_SOFT;
  hspi1.Init.FirstBit = SPI_FIRSTBIT_MSB;
  hspi1.Init.TIMode = SPI_TIMODE_DISABLE;
  hspi1.Init.CRCCalculation = SPI_CRCCALCULATION_DISABLE;
  hspi1.Init.CRCPolynomial = 0x0;
  hspi1.Init.NSSPMode = SPI_NSS_PULSE_DISABLE;
  hspi1.Init.NSSPolarity = SPI_NSS_POLARITY_LOW;
  hspi1.Init.FifoThreshold = SPI_FIFO_THRESHOLD_01DATA;
  hspi1.Init.TxCRCInitializationPattern = SPI_CRC_INITIALIZATION_ALL_ZERO_PATTERN;
  hspi1.Init.RxCRCInitializationPattern = SPI_CRC_INITIALIZATION_ALL_ZERO_PATTERN;
  hspi1.Init.MasterSSIdleness = SPI_MASTER_SS_IDLENESS_00CYCLE;
  hspi1.Init.MasterInterDataIdleness = SPI_MASTER_INTERDATA_IDLENESS_00CYCLE;
  hspi1.Init.MasterReceiverAutoSusp = SPI_MASTER_RX_AUTOSUSP_DISABLE;
  hspi1.Init.MasterKeepIOState = SPI_MASTER_KEEP_IO_STATE_DISABLE;
  hspi1.Init.IOSwap = SPI_IO_SWAP_DISABLE;
  if (HAL_SPI_Init(&hspi1) != HAL_OK)
  {
    Error_Handler();
  }

}

static void MX_SPI2_Init(void)
{

  /* SPI2 parameter configuration*/
  hspi2.Instance = SPI2;
  hspi2.Init.Mode = SPI_MODE_SLAVE;
  hspi2.Init.Direction = SPI_DIRECTION_2LINES_RXONLY;
  hspi2.Init.DataSize = SPI_DATASIZE_16BIT;
  hspi2.Init.CLKPolarity = SPI_POLARITY_HIGH;
  hspi2.Init.CLKPhase = SPI_PHASE_2EDGE;
  hspi2.Init.NSS = SPI_NSS_SOFT;
  hspi2.Init.FirstBit = SPI_FIRSTBIT_MSB;
  hspi2.Init.TIMode = SPI_TIMODE_DISABLE;
  hspi2.Init.CRCCalculation = SPI_CRCCALCULATION_DISABLE;
  hspi2.Init.CRCPolynomial = 0x0;
  hspi2.Init.NSSPMode = SPI_NSS_PULSE_DISABLE;
  hspi2.Init.NSSPolarity = SPI_NSS_POLARITY_LOW;
  hspi2.Init.FifoThreshold = SPI_FIFO_THRESHOLD_01DATA;
  hspi2.Init.TxCRCInitializationPattern = SPI_CRC_INITIALIZATION_ALL_ZERO_PATTERN;
  hspi2.Init.RxCRCInitializationPattern = SPI_CRC_INITIALIZATION_ALL_ZERO_PATTERN;
  hspi2.Init.MasterSSIdleness = SPI_MASTER_SS_IDLENESS_00CYCLE;
  hspi2.Init.MasterInterDataIdleness = SPI_MASTER_INTERDATA_IDLENESS_00CYCLE;
  hspi2.Init.MasterReceiverAutoSusp = SPI_MASTER_RX_AUTOSUSP_DISABLE;
  hspi2.Init.MasterKeepIOState = SPI_MASTER_KEEP_IO_STATE_DISABLE;
  hspi2.Init.IOSwap = SPI_IO_SWAP_DISABLE;
  if (HAL_SPI_Init(&hspi2) != HAL_OK)
  {
    Error_Handler();
  }

}

static void MX_SPI3_Init(void)
{

  /* SPI3 parameter configuration*/
  hspi3.Instance = SPI3;
  hspi3.Init.Mode = SPI_MODE_SLAVE;
  hspi3.Init.Direction = SPI_DIRECTION_2LINES_RXONLY;
  hspi3.Init.DataSize = SPI_DATASIZE_16BIT;
  hspi3.Init.CLKPolarity = SPI_POLARITY_HIGH;
  hspi3.Init.CLKPhase = SPI_PHASE_2EDGE;
  hspi3.Init.NSS = SPI_NSS_SOFT;
  hspi3.Init.FirstBit = SPI_FIRSTBIT_MSB;
  hspi3.Init.TIMode = SPI_TIMODE_DISABLE;
  hspi3.Init.CRCCalculation = SPI_CRCCALCULATION_DISABLE;
  hspi3.Init.CRCPolynomial = 0x0;
  hspi3.Init.NSSPMode = SPI_NSS_PULSE_DISABLE;
  hspi3.Init.NSSPolarity = SPI_NSS_POLARITY_LOW;
  hspi3.Init.FifoThreshold = SPI_FIFO_THRESHOLD_01DATA;
  hspi3.Init.TxCRCInitializationPattern = SPI_CRC_INITIALIZATION_ALL_ZERO_PATTERN;
  hspi3.Init.RxCRCInitializationPattern = SPI_CRC_INITIALIZATION_ALL_ZERO_PATTERN;
  hspi3.Init.MasterSSIdleness = SPI_MASTER_SS_IDLENESS_00CYCLE;
  hspi3.Init.MasterInterDataIdleness = SPI_MASTER_INTERDATA_IDLENESS_00CYCLE;
  hspi3.Init.MasterReceiverAutoSusp = SPI_MASTER_RX_AUTOSUSP_DISABLE;
  hspi3.Init.MasterKeepIOState = SPI_MASTER_KEEP_IO_STATE_DISABLE;
  hspi3.Init.IOSwap = SPI_IO_SWAP_DISABLE;
  if (HAL_SPI_Init(&hspi3) != HAL_OK)
  {
    Error_Handler();
  }

}

static void MX_SPI4_Init(void)
{

  /* SPI4 parameter configuration*/
  hspi4.Instance = SPI4;
  hspi4.Init.Mode = SPI_MODE_SLAVE;
  hspi4.Init.Direction = SPI_DIRECTION_2LINES_RXONLY;
  hspi4.Init.DataSize = SPI_DATASIZE_16BIT;
  hspi4.Init.CLKPolarity = SPI_POLARITY_HIGH;
  hspi4.Init.CLKPhase = SPI_PHASE_2EDGE;
  hspi4.Init.NSS = SPI_NSS_SOFT;
  hspi4.Init.FirstBit = SPI_FIRSTBIT_MSB;
  hspi4.Init.TIMode = SPI_TIMODE_DISABLE;
  hspi4.Init.CRCCalculation = SPI_CRCCALCULATION_DISABLE;
  hspi4.Init.CRCPolynomial = 0x0;
  hspi4.Init.NSSPMode = SPI_NSS_PULSE_DISABLE;
  hspi4.Init.NSSPolarity = SPI_NSS_POLARITY_LOW;
  hspi4.Init.FifoThreshold = SPI_FIFO_THRESHOLD_01DATA;
  hspi4.Init.TxCRCInitializationPattern = SPI_CRC_INITIALIZATION_ALL_ZERO_PATTERN;
  hspi4.Init.RxCRCInitializationPattern = SPI_CRC_INITIALIZATION_ALL_ZERO_PATTERN;
  hspi4.Init.MasterSSIdleness = SPI_MASTER_SS_IDLENESS_00CYCLE;
  hspi4.Init.MasterInterDataIdleness = SPI_MASTER_INTERDATA_IDLENESS_00CYCLE;
  hspi4.Init.MasterReceiverAutoSusp = SPI_MASTER_RX_AUTOSUSP_DISABLE;
  hspi4.Init.MasterKeepIOState = SPI_MASTER_KEEP_IO_STATE_DISABLE;
  hspi4.Init.IOSwap = SPI_IO_SWAP_DISABLE;
  if (HAL_SPI_Init(&hspi4) != HAL_OK)
  {
    Error_Handler();
  }

}

static void MX_SPI5_Init(void)
{

  /* SPI5 parameter configuration*/
  hspi5.Instance = SPI5;
  hspi5.Init.Mode = SPI_MODE_SLAVE;
  hspi5.Init.Direction = SPI_DIRECTION_2LINES_RXONLY;
  hspi5.Init.DataSize = SPI_DATASIZE_16BIT;
  hspi5.Init.CLKPolarity = SPI_POLARITY_HIGH;
  hspi5.Init.CLKPhase = SPI_PHASE_2EDGE;
  hspi5.Init.NSS = SPI_NSS_SOFT;
  hspi5.Init.FirstBit = SPI_FIRSTBIT_MSB;
  hspi5.Init.TIMode = SPI_TIMODE_DISABLE;
  hspi5.Init.CRCCalculation = SPI_CRCCALCULATION_DISABLE;
  hspi5.Init.CRCPolynomial = 0x0;
  hspi5.Init.NSSPMode = SPI_NSS_PULSE_DISABLE;
  hspi5.Init.NSSPolarity = SPI_NSS_POLARITY_LOW;
  hspi5.Init.FifoThreshold = SPI_FIFO_THRESHOLD_01DATA;
  hspi5.Init.TxCRCInitializationPattern = SPI_CRC_INITIALIZATION_ALL_ZERO_PATTERN;
  hspi5.Init.RxCRCInitializationPattern = SPI_CRC_INITIALIZATION_ALL_ZERO_PATTERN;
  hspi5.Init.MasterSSIdleness = SPI_MASTER_SS_IDLENESS_00CYCLE;
  hspi5.Init.MasterInterDataIdleness = SPI_MASTER_INTERDATA_IDLENESS_00CYCLE;
  hspi5.Init.MasterReceiverAutoSusp = SPI_MASTER_RX_AUTOSUSP_DISABLE;
  hspi5.Init.MasterKeepIOState = SPI_MASTER_KEEP_IO_STATE_DISABLE;
  hspi5.Init.IOSwap = SPI_IO_SWAP_DISABLE;
  if (HAL_SPI_Init(&hspi5) != HAL_OK)
  {
    Error_Handler();
  }

}

static void MX_SPI6_Init(void)
{

  /* USER CODE BEGIN SPI6_Init 0 */
	HAL_GPIO_WritePin(GPIOG, GPIO_PIN_13, GPIO_PIN_SET);   // SCK High

  /* USER CODE END SPI6_Init 0 */

  /* SPI6 parameter configuration*/
  hspi6.Instance = SPI6;
  hspi6.Init.Mode = SPI_MODE_MASTER;
  hspi6.Init.Direction = SPI_DIRECTION_2LINES;
  hspi6.Init.DataSize = SPI_DATASIZE_16BIT;
  hspi6.Init.CLKPolarity = SPI_POLARITY_HIGH;
  hspi6.Init.CLKPhase = SPI_PHASE_1EDGE;
  hspi6.Init.NSS = SPI_NSS_SOFT;
  hspi6.Init.BaudRatePrescaler = SPI_BAUDRATEPRESCALER_4;
  hspi6.Init.FirstBit = SPI_FIRSTBIT_MSB;
  hspi6.Init.TIMode = SPI_TIMODE_DISABLE;
  hspi6.Init.CRCCalculation = SPI_CRCCALCULATION_DISABLE;
  hspi6.Init.CRCPolynomial = 0x0;
  hspi6.Init.NSSPMode = SPI_NSS_PULSE_ENABLE;
  hspi6.Init.NSSPolarity = SPI_NSS_POLARITY_LOW;
  hspi6.Init.FifoThreshold = SPI_FIFO_THRESHOLD_01DATA;
  hspi6.Init.TxCRCInitializationPattern = SPI_CRC_INITIALIZATION_ALL_ZERO_PATTERN;
  hspi6.Init.RxCRCInitializationPattern = SPI_CRC_INITIALIZATION_ALL_ZERO_PATTERN;
  hspi6.Init.MasterSSIdleness = SPI_MASTER_SS_IDLENESS_00CYCLE;
  hspi6.Init.MasterInterDataIdleness = SPI_MASTER_INTERDATA_IDLENESS_00CYCLE;
  hspi6.Init.MasterReceiverAutoSusp = SPI_MASTER_RX_AUTOSUSP_DISABLE;
  hspi6.Init.MasterKeepIOState = SPI_MASTER_KEEP_IO_STATE_ENABLE;
  hspi6.Init.IOSwap = SPI_IO_SWAP_DISABLE;
  if (HAL_SPI_Init(&hspi6) != HAL_OK)
  {
    Error_Handler();
  }

}

static void MX_TIM1_Init(void)
{

  TIM_ClockConfigTypeDef sClockSourceConfig = {0};
  TIM_MasterConfigTypeDef sMasterConfig = {0};
  TIM_OC_InitTypeDef sConfigOC = {0};
  TIM_BreakDeadTimeConfigTypeDef sBreakDeadTimeConfig = {0};

  htim1.Instance = TIM1;
  htim1.Init.Prescaler = 0;
  htim1.Init.CounterMode = TIM_COUNTERMODE_UP;
  htim1.Init.Period = 1919;
  htim1.Init.ClockDivision = TIM_CLOCKDIVISION_DIV1;
  htim1.Init.RepetitionCounter = 0;
  htim1.Init.AutoReloadPreload = TIM_AUTORELOAD_PRELOAD_DISABLE;
  if (HAL_TIM_Base_Init(&htim1) != HAL_OK)
  {
    Error_Handler();
  }
  sClockSourceConfig.ClockSource = TIM_CLOCKSOURCE_INTERNAL;
  if (HAL_TIM_ConfigClockSource(&htim1, &sClockSourceConfig) != HAL_OK)
  {
    Error_Handler();
  }
  if (HAL_TIM_PWM_Init(&htim1) != HAL_OK)
  {
    Error_Handler();
  }
  sMasterConfig.MasterOutputTrigger = TIM_TRGO_RESET;
  sMasterConfig.MasterOutputTrigger2 = TIM_TRGO2_RESET;
  sMasterConfig.MasterSlaveMode = TIM_MASTERSLAVEMODE_DISABLE;
  if (HAL_TIMEx_MasterConfigSynchronization(&htim1, &sMasterConfig) != HAL_OK)
  {
    Error_Handler();
  }
  sConfigOC.OCMode = TIM_OCMODE_PWM1;
  sConfigOC.Pulse = 10;
  sConfigOC.OCPolarity = TIM_OCPOLARITY_HIGH;
  sConfigOC.OCFastMode = TIM_OCFAST_DISABLE;
  sConfigOC.OCIdleState = TIM_OCIDLESTATE_RESET;
  sConfigOC.OCNIdleState = TIM_OCNIDLESTATE_RESET;
  if (HAL_TIM_PWM_ConfigChannel(&htim1, &sConfigOC, TIM_CHANNEL_4) != HAL_OK)
  {
    Error_Handler();
  }
  sBreakDeadTimeConfig.OffStateRunMode = TIM_OSSR_DISABLE;
  sBreakDeadTimeConfig.OffStateIDLEMode = TIM_OSSI_DISABLE;
  sBreakDeadTimeConfig.LockLevel = TIM_LOCKLEVEL_OFF;
  sBreakDeadTimeConfig.DeadTime = 0;
  sBreakDeadTimeConfig.BreakState = TIM_BREAK_DISABLE;
  sBreakDeadTimeConfig.BreakPolarity = TIM_BREAKPOLARITY_HIGH;
  sBreakDeadTimeConfig.BreakFilter = 0;
  sBreakDeadTimeConfig.Break2State = TIM_BREAK2_DISABLE;
  sBreakDeadTimeConfig.Break2Polarity = TIM_BREAK2POLARITY_HIGH;
  sBreakDeadTimeConfig.Break2Filter = 0;
  sBreakDeadTimeConfig.AutomaticOutput = TIM_AUTOMATICOUTPUT_DISABLE;
  if (HAL_TIMEx_ConfigBreakDeadTime(&htim1, &sBreakDeadTimeConfig) != HAL_OK)
  {
    Error_Handler();
  }
  HAL_TIM_MspPostInit(&htim1);

}

static void MX_TIM6_Init(void)
{

  TIM_MasterConfigTypeDef sMasterConfig = {0};

  htim6.Instance = TIM6;
  htim6.Init.Prescaler = 3749;
  htim6.Init.CounterMode = TIM_COUNTERMODE_UP;
  htim6.Init.Period = 249;
  htim6.Init.AutoReloadPreload = TIM_AUTORELOAD_PRELOAD_DISABLE;
  if (HAL_TIM_Base_Init(&htim6) != HAL_OK)
  {
    Error_Handler();
  }
  sMasterConfig.MasterOutputTrigger = TIM_TRGO_UPDATE;
  sMasterConfig.MasterSlaveMode = TIM_MASTERSLAVEMODE_DISABLE;
  if (HAL_TIMEx_MasterConfigSynchronization(&htim6, &sMasterConfig) != HAL_OK)
  {
    Error_Handler();
  }

}

static void MX_USART1_UART_Init(void)
{

  huart1.Instance = USART1;
  huart1.Init.BaudRate = 900000;
  huart1.Init.WordLength = UART_WORDLENGTH_8B;
  huart1.Init.StopBits = UART_STOPBITS_1;
  huart1.Init.Parity = UART_PARITY_NONE;
  huart1.Init.Mode = UART_MODE_TX_RX;
  huart1.Init.HwFlowCtl = UART_HWCONTROL_NONE;
  huart1.Init.OverSampling = UART_OVERSAMPLING_16;
  huart1.Init.OneBitSampling = UART_ONE_BIT_SAMPLE_DISABLE;
  huart1.Init.ClockPrescaler = UART_PRESCALER_DIV1;
  huart1.AdvancedInit.AdvFeatureInit = UART_ADVFEATURE_NO_INIT;
  if (HAL_UART_Init(&huart1) != HAL_OK)
  {
    Error_Handler();
  }
  if (HAL_UARTEx_SetTxFifoThreshold(&huart1, UART_TXFIFO_THRESHOLD_1_8) != HAL_OK)
  {
    Error_Handler();
  }
  if (HAL_UARTEx_SetRxFifoThreshold(&huart1, UART_RXFIFO_THRESHOLD_1_8) != HAL_OK)
  {
    Error_Handler();
  }
  if (HAL_UARTEx_DisableFifoMode(&huart1) != HAL_OK)
  {
    Error_Handler();
  }

}

static void MX_BDMA_Init(void)
{

  /* DMA controller clock enable */
  __HAL_RCC_BDMA_CLK_ENABLE();

  /* DMA interrupt init */
  /* BDMA_Channel0_IRQn interrupt configuration */
  HAL_NVIC_SetPriority(BDMA_Channel0_IRQn, 0, 0);
  HAL_NVIC_EnableIRQ(BDMA_Channel0_IRQn);
  /* BDMA_Channel1_IRQn interrupt configuration */
  HAL_NVIC_SetPriority(BDMA_Channel1_IRQn, 0, 0);
  HAL_NVIC_EnableIRQ(BDMA_Channel1_IRQn);

}

static void MX_DMA_Init(void)
{

  /* DMA controller clock enable */
  __HAL_RCC_DMA1_CLK_ENABLE();
  __HAL_RCC_DMA2_CLK_ENABLE();

  /* DMA interrupt init */
  /* DMA1_Stream0_IRQn interrupt configuration */
  HAL_NVIC_SetPriority(DMA1_Stream0_IRQn, 14, 0);
  HAL_NVIC_EnableIRQ(DMA1_Stream0_IRQn);
  /* DMA1_Stream1_IRQn interrupt configuration */
  HAL_NVIC_SetPriority(DMA1_Stream1_IRQn, 14, 0);
  HAL_NVIC_EnableIRQ(DMA1_Stream1_IRQn);
  /* DMA1_Stream2_IRQn interrupt configuration */
  HAL_NVIC_SetPriority(DMA1_Stream2_IRQn, 14, 0);
  HAL_NVIC_EnableIRQ(DMA1_Stream2_IRQn);
  /* DMA1_Stream3_IRQn interrupt configuration */
  HAL_NVIC_SetPriority(DMA1_Stream3_IRQn, 14, 0);
  HAL_NVIC_EnableIRQ(DMA1_Stream3_IRQn);
  /* DMA1_Stream4_IRQn interrupt configuration */
  HAL_NVIC_SetPriority(DMA1_Stream4_IRQn, 14, 0);
  HAL_NVIC_EnableIRQ(DMA1_Stream4_IRQn);
  /* DMA1_Stream5_IRQn interrupt configuration */
  HAL_NVIC_SetPriority(DMA1_Stream5_IRQn, 0, 0);
  HAL_NVIC_EnableIRQ(DMA1_Stream5_IRQn);
  /* DMA2_Stream0_IRQn interrupt configuration */
  HAL_NVIC_SetPriority(DMA2_Stream0_IRQn, 0, 0);
  HAL_NVIC_EnableIRQ(DMA2_Stream0_IRQn);
  /* DMAMUX1_OVR_IRQn interrupt configuration */
  HAL_NVIC_SetPriority(DMAMUX1_OVR_IRQn, 0, 0);
  HAL_NVIC_EnableIRQ(DMAMUX1_OVR_IRQn);

}

/**
  * Enable MDMA controller clock
  * Configure MDMA for global transfers
  *   hmdma_mdma_channel0_sw_0
  */
static void MX_MDMA_Init(void)
{

  /* MDMA controller clock enable */
  __HAL_RCC_MDMA_CLK_ENABLE();
  /* Local variables */

  /* Configure MDMA channel MDMA_Channel0 */
  /* Configure MDMA request hmdma_mdma_channel0_sw_0 on MDMA_Channel0 */
  hmdma_mdma_channel0_sw_0.Instance = MDMA_Channel0;
  hmdma_mdma_channel0_sw_0.Init.Request = MDMA_REQUEST_SW;
  hmdma_mdma_channel0_sw_0.Init.TransferTriggerMode = MDMA_BLOCK_TRANSFER;
  hmdma_mdma_channel0_sw_0.Init.Priority = MDMA_PRIORITY_VERY_HIGH;
  hmdma_mdma_channel0_sw_0.Init.Endianness = MDMA_LITTLE_ENDIANNESS_PRESERVE;
  hmdma_mdma_channel0_sw_0.Init.SourceInc = MDMA_SRC_INC_WORD;
  hmdma_mdma_channel0_sw_0.Init.DestinationInc = MDMA_DEST_INC_WORD;
  hmdma_mdma_channel0_sw_0.Init.SourceDataSize = MDMA_SRC_DATASIZE_WORD;
  hmdma_mdma_channel0_sw_0.Init.DestDataSize = MDMA_DEST_DATASIZE_WORD;
  hmdma_mdma_channel0_sw_0.Init.DataAlignment = MDMA_DATAALIGN_PACKENABLE;
  hmdma_mdma_channel0_sw_0.Init.BufferTransferLength = 256;
  hmdma_mdma_channel0_sw_0.Init.SourceBurst = MDMA_SOURCE_BURST_SINGLE;
  hmdma_mdma_channel0_sw_0.Init.DestBurst = MDMA_DEST_BURST_SINGLE;
  hmdma_mdma_channel0_sw_0.Init.SourceBlockAddressOffset = 0;
  hmdma_mdma_channel0_sw_0.Init.DestBlockAddressOffset = 0;
  if (HAL_MDMA_Init(&hmdma_mdma_channel0_sw_0) != HAL_OK)
  {
    Error_Handler();
  }

  /* MDMA interrupt initialization */
  /* MDMA_IRQn interrupt configuration */
  HAL_NVIC_SetPriority(MDMA_IRQn, 0, 0);
  HAL_NVIC_EnableIRQ(MDMA_IRQn);

}

static void MX_GPIO_Init(void)
{
  GPIO_InitTypeDef GPIO_InitStruct = {0};

  /* GPIO Ports Clock Enable */
  __HAL_RCC_GPIOE_CLK_ENABLE();
  __HAL_RCC_GPIOC_CLK_ENABLE();
  __HAL_RCC_GPIOF_CLK_ENABLE();
  __HAL_RCC_GPIOH_CLK_ENABLE();
  __HAL_RCC_GPIOA_CLK_ENABLE();
  __HAL_RCC_GPIOB_CLK_ENABLE();
  __HAL_RCC_GPIOD_CLK_ENABLE();
  __HAL_RCC_GPIOG_CLK_ENABLE();

  /*Configure GPIO pin Output Level */
  HAL_GPIO_WritePin(CS_GPIO_Port, CS_Pin, GPIO_PIN_SET);

  /*Configure GPIO pin Output Level */
  HAL_GPIO_WritePin(GPIOD, LEDG_Pin|LEDY_Pin|LEDR_Pin, GPIO_PIN_RESET);

  /*Configure GPIO pin : FRSTDATA_Pin */
  GPIO_InitStruct.Pin = FRSTDATA_Pin;
  GPIO_InitStruct.Mode = GPIO_MODE_INPUT;
  GPIO_InitStruct.Pull = GPIO_NOPULL;
  HAL_GPIO_Init(FRSTDATA_GPIO_Port, &GPIO_InitStruct);

  /*Configure GPIO pin : BUSY_Pin */
  GPIO_InitStruct.Pin = BUSY_Pin;
  GPIO_InitStruct.Mode = GPIO_MODE_IT_RISING;
  GPIO_InitStruct.Pull = GPIO_NOPULL;
  HAL_GPIO_Init(BUSY_GPIO_Port, &GPIO_InitStruct);

  /*Configure GPIO pin : CS_Pin */
  GPIO_InitStruct.Pin = CS_Pin;
  GPIO_InitStruct.Mode = GPIO_MODE_OUTPUT_PP;
  GPIO_InitStruct.Pull = GPIO_NOPULL;
  GPIO_InitStruct.Speed = GPIO_SPEED_FREQ_LOW;
  HAL_GPIO_Init(CS_GPIO_Port, &GPIO_InitStruct);

  /*Configure GPIO pins : LEDG_Pin LEDY_Pin LEDR_Pin */
  GPIO_InitStruct.Pin = LEDG_Pin|LEDY_Pin|LEDR_Pin;
  GPIO_InitStruct.Mode = GPIO_MODE_OUTPUT_PP;
  GPIO_InitStruct.Pull = GPIO_NOPULL;
  GPIO_InitStruct.Speed = GPIO_SPEED_FREQ_LOW;
  HAL_GPIO_Init(GPIOD, &GPIO_InitStruct);

  /* EXTI interrupt init*/
  HAL_NVIC_SetPriority(BUSY_EXTI_IRQn, 2, 0);
  HAL_NVIC_EnableIRQ(BUSY_EXTI_IRQn);

}

 /* MPU Configuration */

void MPU_Config(void)
{
  MPU_Region_InitTypeDef MPU_InitStruct = {0};

  /* Disables the MPU */
  HAL_MPU_Disable();

  /** Initializes and configures the Region and the memory to be protected
  */
  MPU_InitStruct.Enable = MPU_REGION_ENABLE;
  MPU_InitStruct.Number = MPU_REGION_NUMBER0;
  MPU_InitStruct.BaseAddress = 0x0;
  MPU_InitStruct.Size = MPU_REGION_SIZE_4GB;
  MPU_InitStruct.SubRegionDisable = 0x87;
  MPU_InitStruct.TypeExtField = MPU_TEX_LEVEL0;
  MPU_InitStruct.AccessPermission = MPU_REGION_NO_ACCESS;
  MPU_InitStruct.DisableExec = MPU_INSTRUCTION_ACCESS_DISABLE;
  MPU_InitStruct.IsShareable = MPU_ACCESS_SHAREABLE;
  MPU_InitStruct.IsCacheable = MPU_ACCESS_NOT_CACHEABLE;
  MPU_InitStruct.IsBufferable = MPU_ACCESS_NOT_BUFFERABLE;

  HAL_MPU_ConfigRegion(&MPU_InitStruct);
  /* Enables the MPU */
  HAL_MPU_Enable(MPU_PRIVILEGED_DEFAULT);

}

void Error_Handler(void)
{
  /* USER CODE BEGIN Error_Handler_Debug */
    /* User can add his own implementation to report the HAL error return state
     */
	hydrophone_interface_stop_datastream();
    __disable_irq();
    HAL_GPIO_WritePin(GREEN_LED, GPIO_PIN_RESET);
    HAL_GPIO_WritePin(YELLOW_LED, GPIO_PIN_RESET);
    while(1){
    	can_errored(); // Tell the can bus that we errored

    	HAL_GPIO_WritePin(RED_LED, GPIO_PIN_SET);
    	utils_DWT_delay_ms(100);
    	HAL_GPIO_WritePin(RED_LED, GPIO_PIN_RESET);

    	HAL_NVIC_SystemReset(); // Turn it off and on again

    	utils_DWT_delay_ms(100); //just in case it for SOME reason doesn't reset, it loops and tries again
    }
  /* USER CODE END Error_Handler_Debug */
}
#ifdef USE_FULL_ASSERT
/**
  * @brief  Reports the name of the source file and the source line number
  *         where the assert_param error has occurred.
  * @param  file: pointer to the source file name
  * @param  line: assert_param error line source number
  * @retval None
  */
void assert_failed(uint8_t *file, uint32_t line)
{
  /* USER CODE BEGIN 6 */
    /* User can add his own implementation to report the file name and line
       number, ex: printf("Wrong parameters value: file %s on line %d\r\n",
       file, line) */
  /* USER CODE END 6 */
}
#endif /* USE_FULL_ASSERT */
